# ATSAMC21N17A register map
Vendor: Microchip Technology; Series: SAMC21; File version: 0
CPU: CM0+ r0p0, selectable endian, MPU, no FPU, 2 interrupt priority bits
Registers are 32-bit, read-write, reset 0x0 unless marked. A register's access mark holds for its fields unless they carry their own. Offsets are from the block's base; [hi:lo] are bit positions; lines under a group give offsets from that group; {n}, {i} and the like mark numbered series.

## HMATRIXHS — HSB Matrix
Base 0x4100A000; register names take the prefix HMATRIXB_
{0x0+4i} MCFG[{i}] (i=0..15) reset 0x2 — Master Configuration
  [2:0] ULBT — Undefined Length Burst Type
    0=INFINITE (Infinite Length); 1=SINGLE (Single Access); 2=FOUR_BEAT (Four Beat Burst); 3=EIGHT_BEAT (Eight Beat Burst); 4=SIXTEEN_BEAT (Sixteen Beat Burst)
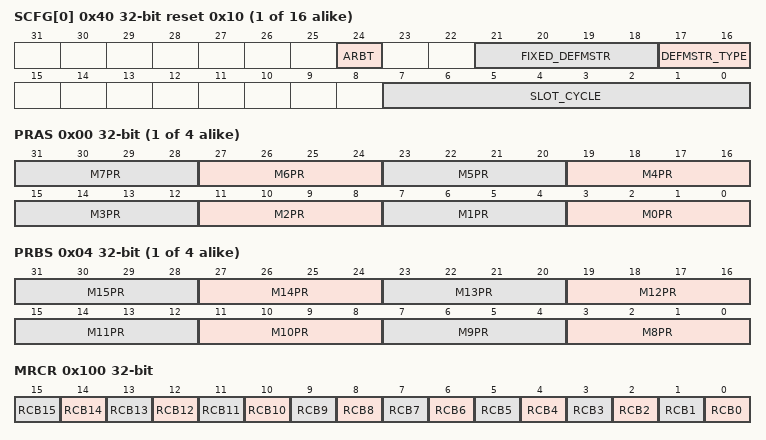
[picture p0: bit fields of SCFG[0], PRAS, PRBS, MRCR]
{0x40+4i} SCFG[{i}] (i=0..15) reset 0x10 — Slave Configuration
  [24] ARBT — Arbitration Type
    0=ROUND_ROBIN (Round-Robin Arbitration); 1=FIXED_PRIORITY (Fixed Priority Arbitration)
  [21:18] FIXED_DEFMSTR — Fixed Index of Default Master
  [17:16] DEFMSTR_TYPE — Default Master Type
    0=NO_DEFAULT (No Default Master. At the end of current slave access, if no other master request is pending, the slave is deconnected from all masters. This resusts in having a one cycle latency for the first transfer of a burst.); 1=LAST_DEFAULT (Last Default Master At the end of current slave access, if no other master request is pending, the slave stay connected with the last master havingaccessed it.This resusts in not having the one cycle latency when the last master re-trying access on the slave.); 2=FIXED_DEFAULT (Fixed Default Master At the end of current slave access, if no other master request is pending, the slave connects with fixed master which numberis in FIXED_DEFMSTR register.This resusts in not having the one cycle latency when the fixed master re-trying access on the slave.)
  [7:0] SLOT_CYCLE — Maximum Number of Allowed Cycles for a Burst
{0x80+8i} PRS[{i}] (i=0..3) group
  0x00 PRAS — Priority A for Slave
    [4n+3:4n] M{n}PR (n=0..7) — Master {n} Priority
  0x04 PRBS — Priority B for Slave
    [4n-29:4n-32] M{n}PR (n=8..15) — Master {n} Priority
0x100 MRCR — Master Remap Control
  [all] fields
    0=DIS (Disable remapped address decoding for master); 1=ENA (Enable remapped address decoding for master)
  [n] RCB{n} (n=0..15) — Remap Command Bit for Master {n}
{0x110+4i} SFR[{i}] (i=0..15) — Special Function
  [31:0] SFR — Special Function Register

## MCLK — Main Clock
Base 0x40000800; register names take the prefix MCLK_
0x01 INTENCLR 8-bit — Interrupt Enable Clear
  [0] CKRDY — Clock Ready Interrupt Enable
0x02 INTENSET 8-bit — Interrupt Enable Set
  [0] CKRDY — Clock Ready Interrupt Enable
0x03 INTFLAG 8-bit reset 0x1 — Interrupt Flag Status and Clear
  [0] CKRDY — Clock Ready
0x04 CPUDIV 8-bit reset 0x1 — CPU Clock Division
  [7:0] CPUDIV — CPU Clock Division Factor
    1=DIV1 (Divide by 1); 2=DIV2 (Divide by 2); 4=DIV4 (Divide by 4); 8=DIV8 (Divide by 8); 16=DIV16 (Divide by 16); 32=DIV32 (Divide by 32); 64=DIV64 (Divide by 64); 128=DIV128 (Divide by 128)
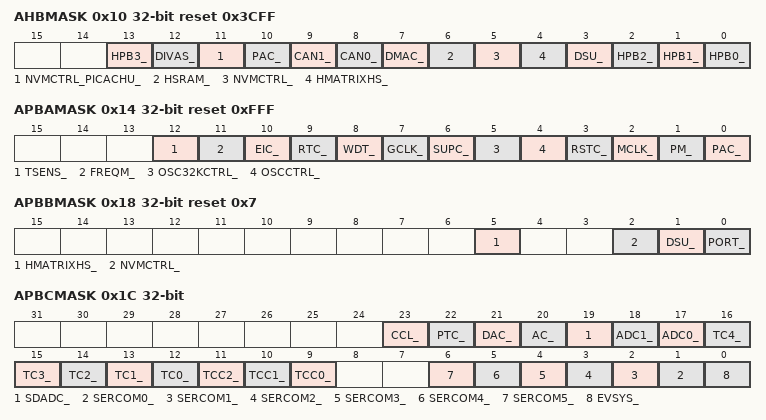
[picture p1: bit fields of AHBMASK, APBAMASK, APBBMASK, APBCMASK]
0x10 AHBMASK reset 0x3CFF
  [13] HPB3_ — HPB3 AHB Clock Mask
  [12] DIVAS_ — DIVAS AHB Clock Mask
  [11] NVMCTRL_PICACHU_ — NVMCTRL_PICACHU AHB Clock Mask
  [10] PAC_ — PAC AHB Clock Mask
  [9] CAN1_ — CAN1 AHB Clock Mask
  [8] CAN0_ — CAN0 AHB Clock Mask
  [7] DMAC_ — DMAC AHB Clock Mask
  [6] HSRAM_ — HSRAM AHB Clock Mask
  [5] NVMCTRL_ — NVMCTRL AHB Clock Mask
  [4] HMATRIXHS_ — HMATRIXHS AHB Clock Mask
  [3] DSU_ — DSU AHB Clock Mask
  [2] HPB2_ — HPB2 AHB Clock Mask
  [1] HPB1_ — HPB1 AHB Clock Mask
  [0] HPB0_ — HPB0 AHB Clock Mask
0x14 APBAMASK reset 0xFFF
  [12] TSENS_ — TSENS APB Clock Enable
  [11] FREQM_ — FREQM APB Clock Enable
  [10] EIC_ — EIC APB Clock Enable
  [9] RTC_ — RTC APB Clock Enable
  [8] WDT_ — WDT APB Clock Enable
  [7] GCLK_ — GCLK APB Clock Enable
  [6] SUPC_ — SUPC APB Clock Enable
  [5] OSC32KCTRL_ — OSC32KCTRL APB Clock Enable
  [4] OSCCTRL_ — OSCCTRL APB Clock Enable
  [3] RSTC_ — RSTC APB Clock Enable
  [2] MCLK_ — MCLK APB Clock Enable
  [1] PM_ — PM APB Clock Enable
  [0] PAC_ — PAC APB Clock Enable
0x18 APBBMASK reset 0x7
  [5] HMATRIXHS_ — HMATRIXHS APB Clock Enable
  [2] NVMCTRL_ — NVMCTRL APB Clock Enable
  [1] DSU_ — DSU APB Clock Enable
  [0] PORT_ — PORT APB Clock Enable
0x1C APBCMASK
  [23] CCL_ — CCL APB Clock Enable
  [22] PTC_ — PTC APB Clock Enable
  [21] DAC_ — DAC APB Clock Enable
  [20] AC_ — AC APB Clock Enable
  [19] SDADC_ — SDADC APB Clock Enable
  [18] ADC1_ — ADC1 APB Clock Enable
  [17] ADC0_ — ADC0 APB Clock Enable
  [n+12] TC{n}_ (n=0..4) — TC{n} APB Clock Enable
  [11] TCC2_ — TCC2 APB Clock Enable
  [10] TCC1_ — TCC1 APB Clock Enable
  [9] TCC0_ — TCC0 APB Clock Enable
  [n+1] SERCOM{n}_ (n=0..5) — SERCOM{n} APB Clock Enable
  [0] EVSYS_ — EVSYS APB Clock Enable
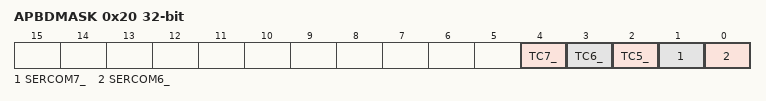
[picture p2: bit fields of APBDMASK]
0x20 APBDMASK
  [4] TC7_ — TC7 APB Clock Enable
  [3] TC6_ — TC6 APB Clock Enable
  [2] TC5_ — TC5 APB Clock Enable
  [1] SERCOM7_ — SERCOM7 APB Clock Enable
  [0] SERCOM6_ — SERCOM6 APB Clock Enable
